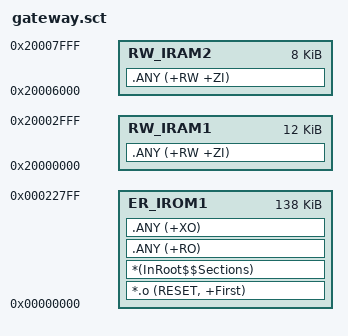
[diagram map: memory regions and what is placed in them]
; *************************************************************
; *** Scatter-Loading Description File for Gateway (with BLE) ***
; *** RAM1: 0x20000000 12KB, BLE reserved middle, RAM2: 0x20006000 8KB ***
; *************************************************************

LR_IROM1 0x00000000 0x00022800  {
  ER_IROM1 0x00000000 0x00022800  {
    *.o (RESET, +First)
    *(InRoot$$Sections)
    .ANY (+RO)
    .ANY (+XO)
  }

  RW_IRAM1 0x20000000 0x00003000  {
    .ANY (+RW +ZI)
  }

  RW_IRAM2 0x20006000 0x00002000  {
    .ANY (+RW +ZI)
  }
}
